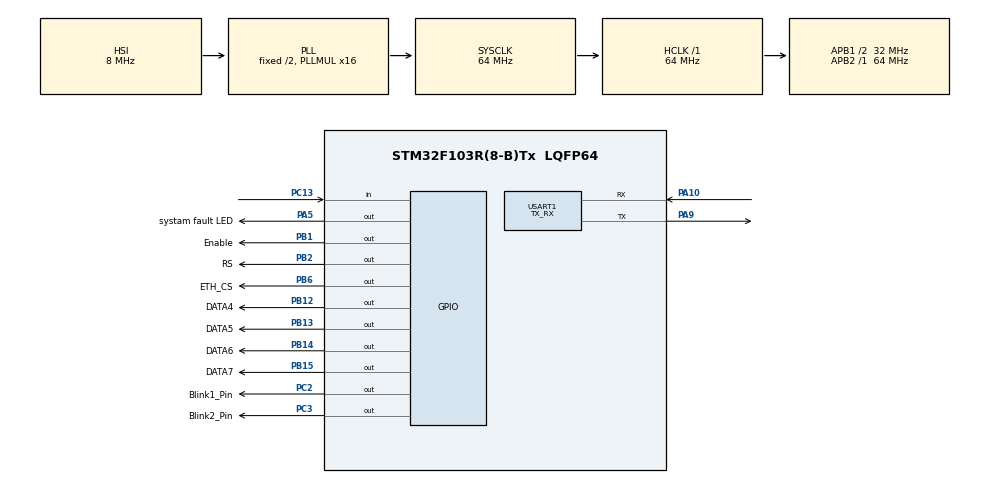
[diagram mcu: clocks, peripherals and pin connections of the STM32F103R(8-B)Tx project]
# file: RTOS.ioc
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Dma.Request0=USART1_RX
Dma.USART1_RX.0.Direction=DMA_PERIPH_TO_MEMORY
Dma.USART1_RX.0.Instance=DMA1_Channel5
Dma.USART1_RX.0.MemDataAlignment=DMA_MDATAALIGN_BYTE
Dma.USART1_RX.0.MemInc=DMA_MINC_ENABLE
Dma.USART1_RX.0.Mode=DMA_NORMAL
Dma.USART1_RX.0.PeriphDataAlignment=DMA_PDATAALIGN_BYTE
Dma.USART1_RX.0.PeriphInc=DMA_PINC_DISABLE
Dma.USART1_RX.0.Priority=DMA_PRIORITY_LOW
Mcu.Family=STM32F1
Mcu.Name=STM32F103R(8-B)Tx
Mcu.Package=LQFP64
NVIC.DMA1_Channel5_IRQn=true\:0\:0\:false\:false\:true\:false\:true\:true
NVIC.PriorityGroup=NVIC_PRIORITYGROUP_4
NVIC.TIM1_UP_IRQn=true\:15\:0\:false\:false\:true\:false\:true\:true
NVIC.TIM2_IRQn=true\:0\:0\:false\:false\:true\:true\:true\:true
NVIC.TimeBase=TIM1_UP_IRQn
NVIC.TimeBaseIP=TIM1
NVIC.USART1_IRQn=true\:0\:0\:false\:false\:true\:true\:true\:true
PA10.Mode=Asynchronous
PA10.Signal=USART1_RX
PA13.GPIO_Label=TMS
PA13.Mode=Serial_Wire
PA13.Signal=SYS_JTMS-SWDIO
PA14.GPIO_Label=TCK
PA14.Mode=Serial_Wire
PA14.Signal=SYS_JTCK-SWCLK
PA2.GPIO_Label=USART_TX
PA2.GPIO_Mode=GPIO_MODE_AF_PP
PA2.GPIO_PuPd=GPIO_NOPULL
PA2.GPIO_Speed=GPIO_SPEED_FREQ_LOW
PA2.Signal=USART2_TX
PA3.GPIO_Label=USART_RX
PA3.GPIO_Mode=GPIO_MODE_AF_PP
PA3.GPIO_PuPd=GPIO_NOPULL
PA3.GPIO_Speed=GPIO_SPEED_FREQ_LOW
PA3.Signal=USART2_RX
PA5.GPIO_Label=systam fault LED
PA5.Signal=GPIO_Output
PA9.Mode=Asynchronous
PA9.Signal=USART1_TX
PB1.GPIO_Label=Enable
PB1.Signal=GPIO_Output
PB12.GPIO_Label=DATA4
PB12.Signal=GPIO_Output
PB13.GPIO_Label=DATA5
PB13.Signal=GPIO_Output
PB14.GPIO_Label=DATA6
PB14.Signal=GPIO_Output
PB15.GPIO_Label=DATA7
PB15.Signal=GPIO_Output
PB2.GPIO_Label=RS
PB2.Signal=GPIO_Output
PB3.GPIO_Label=SWO
PB3.Signal=SYS_JTDO-TRACESWO
PB6.GPIO_Label=ETH_CS
PB6.Signal=GPIO_Output
PC13-TAMPER-RTC.GPIO_PuPd=GPIO_PULLUP
PC13-TAMPER-RTC.Signal=GPIO_Input
PC14-OSC32_IN.Mode=LSE-External-Oscillator
PC14-OSC32_IN.Signal=RCC_OSC32_IN
PC15-OSC32_OUT.Mode=LSE-External-Oscillator
PC15-OSC32_OUT.Signal=RCC_OSC32_OUT
PC2.GPIO_Label=Blink1_Pin
PC2.Signal=GPIO_Output
PC3.GPIO_Label=Blink2_Pin
PC3.Signal=GPIO_Output
PD0-OSC_IN.Mode=HSE-External-Clock-Source
PD0-OSC_IN.Signal=RCC_OSC_IN
PD1-OSC_OUT.Mode=HSE-External-Clock-Source
PD1-OSC_OUT.Signal=RCC_OSC_OUT
ProjectManager.HeapSize=0x200
ProjectManager.StackSize=0x400
ProjectManager.TargetToolchain=STM32CubeIDE
RCC.AHBFreq_Value=64000000
RCC.APB1CLKDivider=RCC_HCLK_DIV2
RCC.APB1Freq_Value=32000000
RCC.APB1TimFreq_Value=64000000
RCC.APB2Freq_Value=64000000
RCC.APB2TimFreq_Value=64000000
RCC.HCLKFreq_Value=64000000
RCC.PLLMUL=RCC_PLL_MUL16
RCC.RTCClockSelection=RCC_RTCCLKSOURCE_LSE
RCC.SYSCLKFreq_VALUE=64000000
RCC.SYSCLKSource=RCC_SYSCLKSOURCE_PLLCLK
RCC.USBFreq_Value=64000000
TIM2.Prescaler=64-1
USART1.Mode=MODE_TX_RX
USART1.VirtualMode=VM_ASYNC
VP_SYS_VS_tim1.Mode=TIM1
VP_TIM2_VS_ClockSourceINT.Mode=Internal
board=NUCLEO-F103RB

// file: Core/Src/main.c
/* USER CODE BEGIN Header */
/**
  ******************************************************************************
  * @file           : main.c
  * @brief          : Main program body
  ******************************************************************************
  * @attention
  *
  * Copyright (c) 2022 STMicroelectronics.
  * All rights reserved.
  *
  * This software is licensed under terms that can be found in the LICENSE file
  * in the root directory of this software component.
  * If no LICENSE file comes with this software, it is provided AS-IS.
  *
  ******************************************************************************
  */
/* USER CODE END Header */
#include "main.h"

/* USER CODE BEGIN Includes */
#include <stdint.h>
#include "OS.h"
#include "lcd_driver.h"
#include "led_driver.h"
/* USER CODE END Includes */

 TIM_HandleTypeDef htim2;

UART_HandleTypeDef huart1;
DMA_HandleTypeDef hdma_usart1_rx;

void SystemClock_Config(void);
static void MX_GPIO_Init(void);
static void MX_DMA_Init(void);
static void MX_USART1_UART_Init(void);
static void MX_TIM2_Init(void);
/* USER CODE BEGIN PFP */
void HAL_UART_RxCpltCallback (UART_HandleTypeDef * huart);

/* USER CODE END PFP */

/* USER CODE BEGIN 0 */
uint32_t blink1_stack[MIN_STACK_SIZE + 100];
uint32_t blink2_stack[MIN_STACK_SIZE + 100];
uint32_t string_stack[MIN_STACK_SIZE + 100];

/* USER CODE END 0 */

int main(void)
{

  /* MCU Configuration--------------------------------------------------------*/

  /* Reset of all peripherals, Initializes the Flash interface and the Systick. */
  HAL_Init();

  /* Configure the system clock */
  SystemClock_Config();

  /* Initialize all configured peripherals */
  MX_GPIO_Init();
  MX_DMA_Init();
  MX_USART1_UART_Init();
  MX_TIM2_Init();
  /* USER CODE BEGIN 2 */
  lcd_init();
  __disable_irq();

  CreateThread(&Blink2, sizeof(blink2_stack)/sizeof(blink2_stack[0]), blink2_stack, "Blink2");
  CreateThread(&Blink1, sizeof(blink1_stack)/sizeof(blink1_stack[0]), blink1_stack, "Blink1");
  CreateThread(&String, sizeof(string_stack)/sizeof(string_stack[0]), string_stack, "String");

  Os_Init();
  /* USER CODE END 2 */

  /* Infinite loop */
  while (1)
  {

  }
}

void SystemClock_Config(void)
{
  RCC_OscInitTypeDef RCC_OscInitStruct = {0};
  RCC_ClkInitTypeDef RCC_ClkInitStruct = {0};

  /** Initializes the RCC Oscillators according to the specified parameters
  * in the RCC_OscInitTypeDef structure.
  */
  RCC_OscInitStruct.OscillatorType = RCC_OSCILLATORTYPE_HSI;
  RCC_OscInitStruct.HSIState = RCC_HSI_ON;
  RCC_OscInitStruct.HSICalibrationValue = RCC_HSICALIBRATION_DEFAULT;
  RCC_OscInitStruct.PLL.PLLState = RCC_PLL_ON;
  RCC_OscInitStruct.PLL.PLLSource = RCC_PLLSOURCE_HSI_DIV2;
  RCC_OscInitStruct.PLL.PLLMUL = RCC_PLL_MUL16;
  if (HAL_RCC_OscConfig(&RCC_OscInitStruct) != HAL_OK)
  {
    Error_Handler();
  }

  /** Initializes the CPU, AHB and APB buses clocks
  */
  RCC_ClkInitStruct.ClockType = RCC_CLOCKTYPE_HCLK|RCC_CLOCKTYPE_SYSCLK
                              |RCC_CLOCKTYPE_PCLK1|RCC_CLOCKTYPE_PCLK2;
  RCC_ClkInitStruct.SYSCLKSource = RCC_SYSCLKSOURCE_PLLCLK;
  RCC_ClkInitStruct.AHBCLKDivider = RCC_SYSCLK_DIV1;
  RCC_ClkInitStruct.APB1CLKDivider = RCC_HCLK_DIV2;
  RCC_ClkInitStruct.APB2CLKDivider = RCC_HCLK_DIV1;

  if (HAL_RCC_ClockConfig(&RCC_ClkInitStruct, FLASH_LATENCY_2) != HAL_OK)
  {
    Error_Handler();
  }
}

static void MX_TIM2_Init(void)
{

  TIM_ClockConfigTypeDef sClockSourceConfig = {0};
  TIM_MasterConfigTypeDef sMasterConfig = {0};

  htim2.Instance = TIM2;
  htim2.Init.Prescaler = 64-1;
  htim2.Init.CounterMode = TIM_COUNTERMODE_UP;
  htim2.Init.Period = 65535;
  htim2.Init.ClockDivision = TIM_CLOCKDIVISION_DIV1;
  htim2.Init.AutoReloadPreload = TIM_AUTORELOAD_PRELOAD_DISABLE;
  if (HAL_TIM_Base_Init(&htim2) != HAL_OK)
  {
    Error_Handler();
  }
  sClockSourceConfig.ClockSource = TIM_CLOCKSOURCE_INTERNAL;
  if (HAL_TIM_ConfigClockSource(&htim2, &sClockSourceConfig) != HAL_OK)
  {
    Error_Handler();
  }
  sMasterConfig.MasterOutputTrigger = TIM_TRGO_RESET;
  sMasterConfig.MasterSlaveMode = TIM_MASTERSLAVEMODE_DISABLE;
  if (HAL_TIMEx_MasterConfigSynchronization(&htim2, &sMasterConfig) != HAL_OK)
  {
    Error_Handler();
  }

}

static void MX_USART1_UART_Init(void)
{

  huart1.Instance = USART1;
  huart1.Init.BaudRate = 115200;
  huart1.Init.WordLength = UART_WORDLENGTH_8B;
  huart1.Init.StopBits = UART_STOPBITS_1;
  huart1.Init.Parity = UART_PARITY_NONE;
  huart1.Init.Mode = UART_MODE_TX_RX;
  huart1.Init.HwFlowCtl = UART_HWCONTROL_NONE;
  huart1.Init.OverSampling = UART_OVERSAMPLING_16;
  if (HAL_UART_Init(&huart1) != HAL_OK)
  {
    Error_Handler();
  }

}

static void MX_DMA_Init(void)
{

  /* DMA controller clock enable */
  __HAL_RCC_DMA1_CLK_ENABLE();

  /* DMA interrupt init */
  /* DMA1_Channel5_IRQn interrupt configuration */
  HAL_NVIC_SetPriority(DMA1_Channel5_IRQn, 0, 0);
  HAL_NVIC_EnableIRQ(DMA1_Channel5_IRQn);

}

static void MX_GPIO_Init(void)
{
  GPIO_InitTypeDef GPIO_InitStruct = {0};

  /* GPIO Ports Clock Enable */
  __HAL_RCC_GPIOC_CLK_ENABLE();
  __HAL_RCC_GPIOD_CLK_ENABLE();
  __HAL_RCC_GPIOA_CLK_ENABLE();
  __HAL_RCC_GPIOB_CLK_ENABLE();

  /*Configure GPIO pin Output Level */
  HAL_GPIO_WritePin(GPIOC, Blink1_Pin_Pin|Blink2_Pin_Pin, GPIO_PIN_RESET);

  /*Configure GPIO pin Output Level */
  HAL_GPIO_WritePin(systam_fault_LED_GPIO_Port, systam_fault_LED_Pin, GPIO_PIN_RESET);

  /*Configure GPIO pin Output Level */
  HAL_GPIO_WritePin(GPIOB, Enable_Pin|RS_Pin|DATA4_Pin|DATA5_Pin
                          |DATA6_Pin|DATA7_Pin|ETH_CS_Pin, GPIO_PIN_RESET);

  /*Configure GPIO pin : PC13 */
  GPIO_InitStruct.Pin = GPIO_PIN_13;
  GPIO_InitStruct.Mode = GPIO_MODE_INPUT;
  GPIO_InitStruct.Pull = GPIO_PULLUP;
  HAL_GPIO_Init(GPIOC, &GPIO_InitStruct);

  /*Configure GPIO pins : Blink1_Pin_Pin Blink2_Pin_Pin */
  GPIO_InitStruct.Pin = Blink1_Pin_Pin|Blink2_Pin_Pin;
  GPIO_InitStruct.Mode = GPIO_MODE_OUTPUT_PP;
  GPIO_InitStruct.Pull = GPIO_NOPULL;
  GPIO_InitStruct.Speed = GPIO_SPEED_FREQ_LOW;
  HAL_GPIO_Init(GPIOC, &GPIO_InitStruct);

  /*Configure GPIO pins : USART_TX_Pin USART_RX_Pin */
  GPIO_InitStruct.Pin = USART_TX_Pin|USART_RX_Pin;
  GPIO_InitStruct.Mode = GPIO_MODE_AF_PP;
  GPIO_InitStruct.Speed = GPIO_SPEED_FREQ_LOW;
  HAL_GPIO_Init(GPIOA, &GPIO_InitStruct);

  /*Configure GPIO pin : systam_fault_LED_Pin */
  GPIO_InitStruct.Pin = systam_fault_LED_Pin;
  GPIO_InitStruct.Mode = GPIO_MODE_OUTPUT_PP;
  GPIO_InitStruct.Pull = GPIO_NOPULL;
  GPIO_InitStruct.Speed = GPIO_SPEED_FREQ_LOW;
  HAL_GPIO_Init(systam_fault_LED_GPIO_Port, &GPIO_InitStruct);

  /*Configure GPIO pins : Enable_Pin RS_Pin DATA4_Pin DATA5_Pin
                           DATA6_Pin DATA7_Pin ETH_CS_Pin */
  GPIO_InitStruct.Pin = Enable_Pin|RS_Pin|DATA4_Pin|DATA5_Pin
                          |DATA6_Pin|DATA7_Pin|ETH_CS_Pin;
  GPIO_InitStruct.Mode = GPIO_MODE_OUTPUT_PP;
  GPIO_InitStruct.Pull = GPIO_NOPULL;
  GPIO_InitStruct.Speed = GPIO_SPEED_FREQ_LOW;
  HAL_GPIO_Init(GPIOB, &GPIO_InitStruct);

}

void HAL_TIM_PeriodElapsedCallback(TIM_HandleTypeDef *htim)
{
  if (htim->Instance == TIM1) {
    HAL_IncTick();
  }
}

void Error_Handler(void)
{
  __disable_irq();
  while (1)
  {
  }
}
